# AE512F80F55D5LS_CM55_HE_View register map
Vendor: Alif Semiconductor; Series: E5; File version: 1.0
CPU: CM55 r1p0, selectable endian, MPU, FPU, double-precision FPU, DSP, VTOR, 8 interrupt priority bits, 1 SAU regions
Registers are 32-bit, read-write, reset 0x0 unless marked. A register's access mark holds for its fields unless they carry their own. Offsets are from the block's base; [hi:lo] are bit positions; 'fields as' and 'values as' point back to an identical list.

## CLKCTL_SYS
Base 0x1A010000
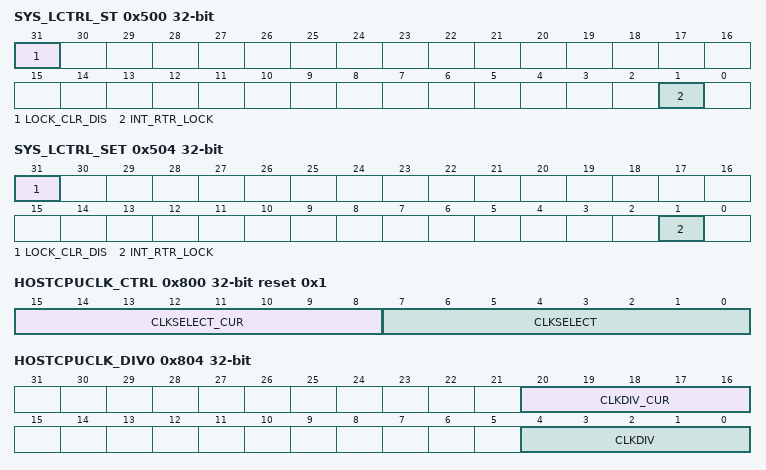
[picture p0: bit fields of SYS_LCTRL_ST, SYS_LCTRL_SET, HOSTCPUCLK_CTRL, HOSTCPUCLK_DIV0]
0x500 SYS_LCTRL_ST ro — System Lock Control Status Register
  [31] LOCK_CLR_DIS — SYS_LCTRL_CLR register behavior indicator
    0=Writes to the SYS_LCTRL_CLR register take effect; 1=Writes to the SYS_LCTRL_CLR register are ignored
  [1] INT_RTR_LOCK — IRQRTR lockdown interface indicator
    0=IRQRTR lockdown interface is de-asserted; 1=IRQRTR lockdown interface is asserted
0x504 SYS_LCTRL_SET — System Lock Control Set Register
  [31] LOCK_CLR_DIS wo — Writing 0x1 to this bit sets the SYS_LCTRL_ST[LOCK_CLR_DIS] bit to 0x1 Writing 0x0 to this bit has no effect on the value of the SYS_LCTRL_ST[LOCK_CLR_DIS] bit This bit always reads as 0x0
  [1] INT_RTR_LOCK wo — Writing 0x1 to this bit sets the SYS_LCTRL_ST[INT_RTR_LOCK] bit to 0x1 Writing 0x0 to this bit has no effect on the value of the SYS_LCTRL_ST[INT_RTR_LOCK] bit This bit always reads as 0x0
0x508 SYS_LCTRL_CLR — System Lock Control Clear Register
  [1] INT_RTR_LOCK wo — Writing 0x1 to this bit sets the SYS_LCTRL_ST[INT_RTR_LOCK] bit to 0x0 Writing 0x0 to this bit has no effect on the value of the SYS_LCTRL_ST[INT_RTR_LOCK] bit This bit always reads as 0x0
0x800 HOSTCPUCLK_CTRL reset 0x1 (reset mask 0xFFFF00FF) — APSS_CLK Clock Control Register
  [15:8] CLKSELECT_CUR ro — Currently selected clock source for APSS_CLK All other values are reserved.
    0=Clock gated; 1=SYST_REFCLK; 2=SYSPLL_CLK divided by HOSTCPUCLK_DIV1[CLKDIV]; 4=CPUPLL_CLK divided by HOSTCPUCLK_DIV0[CLKDIV]
  [7:0] CLKSELECT — Select the clock source for APSS_CLK All other values are reserved. Selecting a reserved value can cause a deadlock.
    values as CLKSELECT_CUR
0x804 HOSTCPUCLK_DIV0 (reset mask 0xFFE0FFFF) — APSS_CLK Clock Divider 0 Register
  [20:16] CLKDIV_CUR ro — Current value of integer divider applied to SYSPLL_CLK
    0=Divided by 1; 1=Divided by 2; 31=Divided by 32
  [4:0] CLKDIV — Select the value of the integer divider applied to SYSPLL_CLK
    0=Divide by 1; 1=Divide by 2; 31=Divide by 32
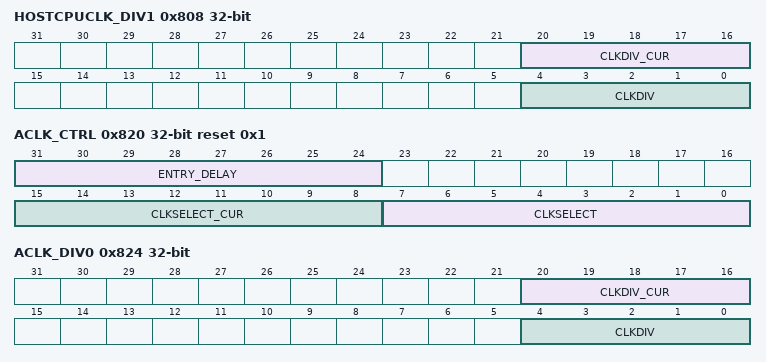
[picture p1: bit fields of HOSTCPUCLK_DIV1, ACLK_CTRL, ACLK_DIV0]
0x808 HOSTCPUCLK_DIV1 (reset mask 0xFFE0FFFF) — APSS_CLK Clock Divider 1 Register
  [20:16] CLKDIV_CUR ro — Current value of integer divider applied to CPUPLL_CLK
    0=Divided by 1; 1=Divided by 2; 31=Divided by 32
  [4:0] CLKDIV — Select the value of the integer divider applied to CPUPLL_CLK
    0=Divide by 1; 1=Divide by 2; 31=Divide by 32
0x820 ACLK_CTRL reset 0x1 (reset mask 0xFFFF00FF) — SYST_ACLK Clock Control Register
  [31:24] ENTRY_DELAY — Configure number of idle clock cycles before clock is gated.
  [15:8] CLKSELECT_CUR ro — Currently selected clock source for SYST_ACLK All other values are reserved.
    0=Clock gated; 1=SYST_REFCLK; 2=SYSPLL_CLK divided by ACLK_DIV0[CLKDIV]
  [7:0] CLKSELECT — Select the clock source for SYST_ACLK All other values are reserved. Selecting a reserved value can cause a deadlock.
    values as CLKSELECT_CUR
0x824 ACLK_DIV0 (reset mask 0xFFE0FFFF) — SYST_ACLK Clock Divider 0 Register
  fields as HOSTCPUCLK_DIV0

## WDT_AP_CTRL
Base 0x1A300000
Same registers: WDT_AP_REFRESH 0x1A310000, WDT_AP_S_CTRL 0x1A320000, WDT_AP_S_REFRESH 0x1A330000
0x00 WDT_WRR wo — Watchdog Refresh Register
  [31:0] WRR — A write to this register causes the watchdog to refresh and start a new watch period. A read has no effect and returns 0.
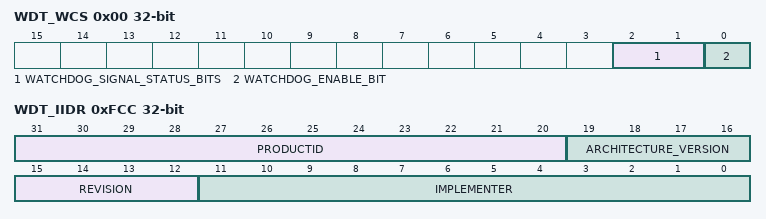
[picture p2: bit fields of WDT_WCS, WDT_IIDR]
0x00 WDT_WCS (alternate view of WDT_WRR) — Watchdog Control and Status Register
  [2:1] WATCHDOG_SIGNAL_STATUS_BITS ro — A read of this bit field indicates the current state of the watchdog signals. A write to these bits has no effect. Bit [2] reflects the status of WDT_AP_IRQ1 and bit [1] reflects the status of WDT_AP_IRQ0.
  [0] WATCHDOG_ENABLE_BIT — A read of this bit indicates the current enabled or disabled state of the watchdog. This bit resets to 0 on watchdog cold reset.
    0=The watchdog is disabled; 1=The watchdog is enabled
0x08 WDT_WOR_31_0 — Watchdog Offset Register, lower bits
  [31:0] WOR_31_0 — The lower 32 bits of the watchdog countdown timer value.
0x0C WDT_WOR_63_32 — Watchdog Offset Register, upper bits
  [15:0] WOR_48_32 — The upper 16 bits of the watchdog countdown timer value.
0x10 WDT_WCV_31_0 — Watchdog Compare Value Register, lower bits
  [31:0] WCV_31_0 — The lower 32 bits of the current watchdog compare value.
0x14 WDT_WCV_63_32 — Watchdog Compare Value Register, upper bits
  [31:0] WCV_63_32 — The upper 32 bits of the current watchdog compare value.
0xFCC WDT_IIDR ro — Interface Identification Register
  [31:20] PRODUCTID — Implementation defined product identifier
  [19:16] ARCHITECTURE_VERSION — WDT architecture version
  [15:12] REVISION — Implementation defined component revision number
  [11:0] IMPLEMENTER — Implementer JEP106 code
